# STM32G07x register map
File version: 1.3
CPU: CM0+ r0p0, little endian, no MPU, no FPU, 3 interrupt priority bits
Registers are 32-bit, read-write, reset 0x0 unless marked. A register's access mark holds for its fields unless they carry their own. Offsets are from the block's base; [hi:lo] are bit positions; {n}, {i} and the like mark numbered series; 'fields as' and 'values as' point back to an identical list.

## SPI1 — Serial peripheral interface/Inter-IC sound
Base 0x40013000
Same registers: SPI2 0x40003800
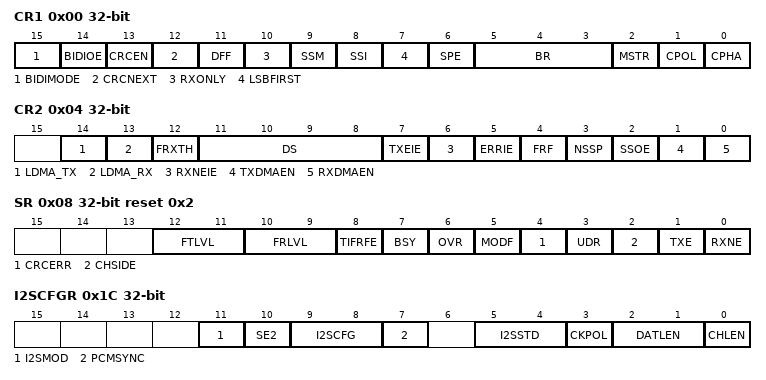
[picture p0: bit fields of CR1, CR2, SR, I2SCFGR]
0x00 CR1 — control register 1
  [15] BIDIMODE — Bidirectional data mode enable
  [14] BIDIOE — Output enable in bidirectional mode
  [13] CRCEN — Hardware CRC calculation enable
  [12] CRCNEXT — CRC transfer next
  [11] DFF — Data frame format
  [10] RXONLY — Receive only
  [9] SSM — Software slave management
  [8] SSI — Internal slave select
  [7] LSBFIRST — Frame format
  [6] SPE — SPI enable
  [5:3] BR — Baud rate control
  [2] MSTR — Master selection
  [1] CPOL — Clock polarity
  [0] CPHA — Clock phase
0x04 CR2 — control register 2
  [14] LDMA_TX — Last DMA transfer for transmission
  [13] LDMA_RX — Last DMA transfer for reception
  [12] FRXTH — FIFO reception threshold
  [11:8] DS — Data size
  [7] TXEIE — Tx buffer empty interrupt enable
  [6] RXNEIE — RX buffer not empty interrupt enable
  [5] ERRIE — Error interrupt enable
  [4] FRF — Frame format
  [3] NSSP — NSS pulse management
  [2] SSOE — SS output enable
  [1] TXDMAEN — Tx buffer DMA enable
  [0] RXDMAEN — Rx buffer DMA enable
0x08 SR access per field reset 0x2 — status register
  [12:11] FTLVL ro — FIFO transmission level
  [10:9] FRLVL ro — FIFO reception level
  [8] TIFRFE ro — TI frame format error
  [7] BSY ro — Busy flag
  [6] OVR ro — Overrun flag
  [5] MODF ro — Mode fault
  [4] CRCERR rw — CRC error flag
  [3] UDR ro — Underrun flag
  [2] CHSIDE ro — Channel side
  [1] TXE ro — Transmit buffer empty
  [0] RXNE ro — Receive buffer not empty
0x0C DR — data register
  [15:0] DR — Data register
0x10 CRCPR reset 0x7 — CRC polynomial register
  [15:0] CRCPOLY
0x14 RXCRCR ro — RX CRC register
  [15:0] RxCRC
0x18 TXCRCR ro — TX CRC register
  [15:0] TxCRC
0x1C I2SCFGR — configuration register
  [11] I2SMOD — I2S mode selection
  [10] SE2 — I2S enable
  [9:8] I2SCFG — I2S configuration mode
  [7] PCMSYNC — PCM frame synchronization
  [5:4] I2SSTD — standard selection
  [3] CKPOL — Inactive state clock polarity
  [2:1] DATLEN — Data length to be transferred
  [0] CHLEN — Channel length (number of bits per audio channel)
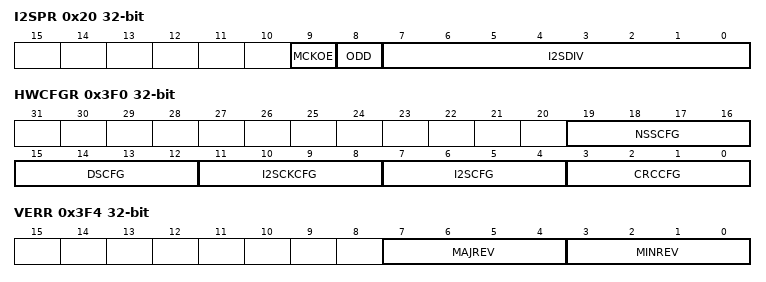
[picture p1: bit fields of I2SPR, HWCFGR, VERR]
0x20 I2SPR — prescaler register
  [9] MCKOE — Master clock output enable
  [8] ODD — Odd factor for the prescaler
  [7:0] I2SDIV — linear prescaler
0x3F0 HWCFGR ro — hardware configuration register
  [19:16] NSSCFG — NSS pulse feature enhancement at SPI master
  [15:12] DSCFG — SPI data size configuration
  [11:8] I2SCKCFG — I2S master clock generator at I2S mode
  [7:4] I2SCFG — I2S mode implementation
  [3:0] CRCCFG — CRC capable at SPI mode
0x3F4 VERR ro — EXTI IP Version register
  [7:4] MAJREV — Major Revision number
  [3:0] MINREV — Minor Revision number
0x3F8 IPIDR ro — EXTI Identification register
  [31:0] IPID — IP Identification
0x3FC SIDR ro — EXTI Size ID register
  [31:0] SID — Size Identification

## COMP — COMP1
Base 0x40010200
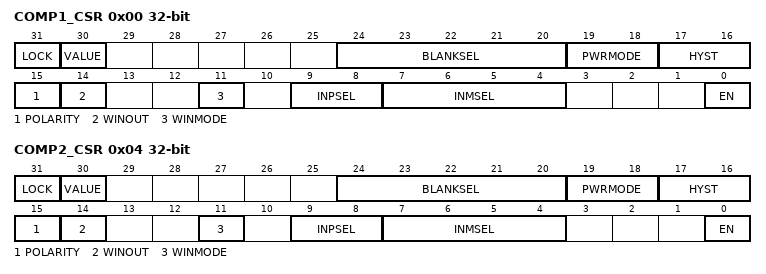
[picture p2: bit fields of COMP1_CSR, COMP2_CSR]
0x00 COMP1_CSR — Comparator 1 control and status register
  [31] LOCK — COMP2_CSR register lock
  [30] VALUE — Comparator 2 output status
  [24:20] BLANKSEL — Comparator 2 blanking source selector
  [19:18] PWRMODE — Comparator 2 power mode selector
  [17:16] HYST — Comparator 2 hysteresis selector
  [15] POLARITY — Comparator 2 polarity selector
  [14] WINOUT — Comparator 2 output selector
  [11] WINMODE — Comparator 2 non-inverting input selector for window mode
  [9:8] INPSEL — Comparator 2 signal selector for non-inverting input
  [7:4] INMSEL — Comparator 2 signal selector for inverting input INM
  [0] EN — COMP channel 1 enable bit
0x04 COMP2_CSR — Comparator 2 control and status register
  fields as COMP1_CSR

## TAMP — Tamper and backup registers
Base 0x4000B000
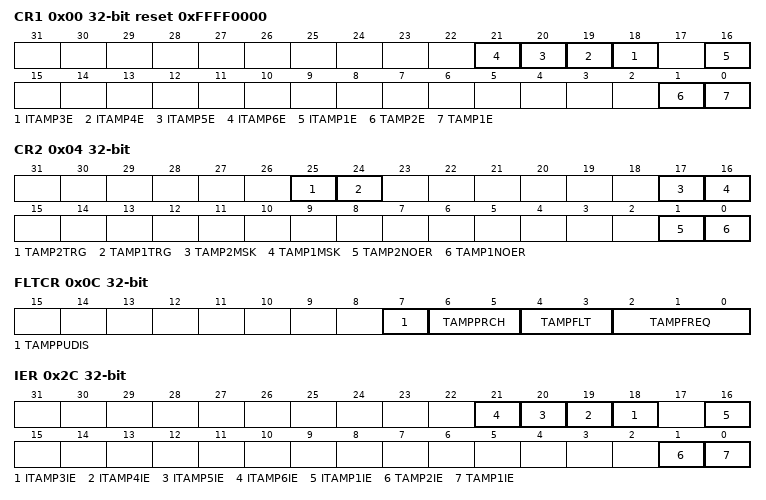
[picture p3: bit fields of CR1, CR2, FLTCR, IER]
0x00 CR1 reset 0xFFFF0000 — control register 1
  [n+15] ITAMP{n}E (n=3..6), [16] ITAMP1E, [1] TAMP2E, [0] TAMP1E
0x04 CR2 — control register 2
  [25] TAMP2TRG, [24] TAMP1TRG, [17] TAMP2MSK, [16] TAMP1MSK, [1] TAMP2NOER, [0] TAMP1NOER
0x0C FLTCR — TAMP filter control register
  [7] TAMPPUDIS, [6:5] TAMPPRCH, [4:3] TAMPFLT, [2:0] TAMPFREQ
0x2C IER — TAMP interrupt enable register
  [n+15] ITAMP{n}IE (n=3..6), [16] ITAMP1IE, [1] TAMP2IE, [0] TAMP1IE
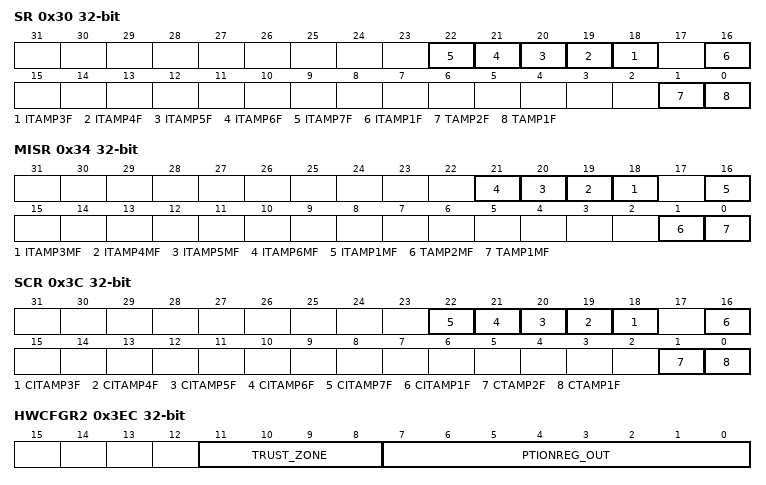
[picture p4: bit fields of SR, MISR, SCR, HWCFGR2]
0x30 SR ro — TAMP status register
  [n+15] ITAMP{n}F (n=3..7), [16] ITAMP1F, [1] TAMP2F, [0] TAMP1F
0x34 MISR ro — TAMP masked interrupt status register
  [n+15] ITAMP{n}MF (n=3..6), [16] ITAMP1MF, [1] TAMP2MF, [0] TAMP1MF
0x3C SCR wo — TAMP status clear register
  [n+15] CITAMP{n}F (n=3..7), [16] CITAMP1F, [1] CTAMP2F, [0] CTAMP1F
{0x100+4i} BKP{i}R (i=0..4) — TAMP backup register
  [31:0] BKP
0x3EC HWCFGR2 ro — TAMP hardware configuration register 2
  [11:8] TRUST_ZONE, [7:0] PTIONREG_OUT
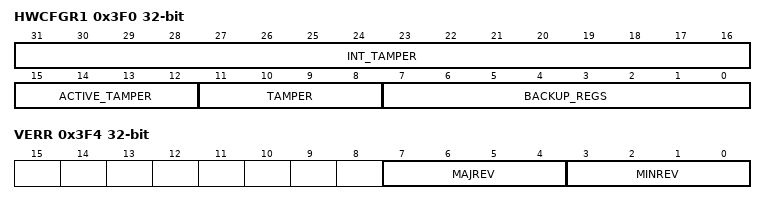
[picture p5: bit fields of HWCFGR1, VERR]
0x3F0 HWCFGR1 ro — TAMP hardware configuration register 1
  [31:16] INT_TAMPER, [15:12] ACTIVE_TAMPER, [11:8] TAMPER, [7:0] BACKUP_REGS
0x3F4 VERR ro — EXTI IP Version register
  [7:4] MAJREV — Major Revision number
  [3:0] MINREV — Minor Revision number
0x3F8 IPIDR ro — EXTI Identification register
  [31:0] IPID — IP Identification
0x3FC SIDR ro — EXTI Size ID register
  [31:0] SID — Size Identification
